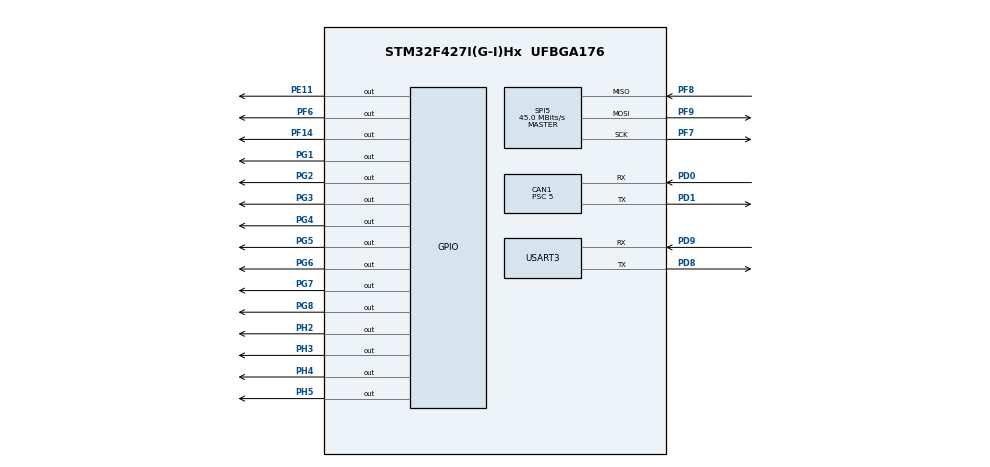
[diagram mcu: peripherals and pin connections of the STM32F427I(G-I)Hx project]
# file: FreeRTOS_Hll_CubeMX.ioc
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CAN1.ABOM=ENABLE
CAN1.BS1=CAN_BS1_3TQ
CAN1.BS2=CAN_BS2_5TQ
CAN1.CalculateBaudRate=1000000
CAN1.CalculateTimeBit=1000
CAN1.CalculateTimeQuantum=111.11111111111111
CAN1.Prescaler=5
Dma.Request0=SPI5_RX
Dma.Request1=SPI5_TX
Dma.SPI5_RX.0.Direction=DMA_PERIPH_TO_MEMORY
Dma.SPI5_RX.0.FIFOMode=DMA_FIFOMODE_DISABLE
Dma.SPI5_RX.0.Instance=DMA2_Stream5
Dma.SPI5_RX.0.MemDataAlignment=DMA_MDATAALIGN_BYTE
Dma.SPI5_RX.0.MemInc=DMA_MINC_ENABLE
Dma.SPI5_RX.0.Mode=DMA_NORMAL
Dma.SPI5_RX.0.PeriphDataAlignment=DMA_PDATAALIGN_BYTE
Dma.SPI5_RX.0.PeriphInc=DMA_PINC_DISABLE
Dma.SPI5_RX.0.Priority=DMA_PRIORITY_VERY_HIGH
Dma.SPI5_TX.1.Direction=DMA_MEMORY_TO_PERIPH
Dma.SPI5_TX.1.FIFOMode=DMA_FIFOMODE_DISABLE
Dma.SPI5_TX.1.Instance=DMA2_Stream4
Dma.SPI5_TX.1.MemDataAlignment=DMA_MDATAALIGN_BYTE
Dma.SPI5_TX.1.MemInc=DMA_MINC_ENABLE
Dma.SPI5_TX.1.Mode=DMA_NORMAL
Dma.SPI5_TX.1.PeriphDataAlignment=DMA_PDATAALIGN_BYTE
Dma.SPI5_TX.1.PeriphInc=DMA_PINC_DISABLE
Dma.SPI5_TX.1.Priority=DMA_PRIORITY_MEDIUM
FREERTOS.BinarySemaphores01=Remote_Sema,Dynamic,NULL
FREERTOS.Tasks01=defaultTask,24,128,StartDefaultTask,Default,NULL,Dynamic,NULL,NULL;REMOTE,24,256,Remote_Task,As weak,NULL,Dynamic,NULL,NULL;CHASSIS,24,256,Chassis_Take,As weak,NULL,Dynamic,NULL,NULL
Mcu.Family=STM32F4
Mcu.Name=STM32F427I(G-I)Hx
Mcu.Package=UFBGA176
NVIC.CAN1_RX0_IRQn=true\:5\:0\:false\:false\:true\:true\:true\:true\:true
NVIC.DMA2_Stream4_IRQn=true\:5\:0\:false\:false\:true\:true\:false\:true\:true
NVIC.DMA2_Stream5_IRQn=true\:5\:0\:false\:false\:true\:false\:false\:true\:true
NVIC.PriorityGroup=NVIC_PRIORITYGROUP_4
NVIC.SPI5_IRQn=true\:5\:0\:false\:false\:true\:true\:true\:true\:true
NVIC.TIM6_DAC_IRQn=true\:15\:0\:false\:false\:true\:false\:false\:true\:true
NVIC.TIM7_IRQn=true\:5\:0\:false\:false\:true\:true\:true\:true\:true
NVIC.TimeBase=TIM6_DAC_IRQn
NVIC.TimeBaseIP=TIM6
NVIC.USART3_IRQn=true\:5\:0\:false\:false\:true\:true\:true\:true\:true
PA13.Mode=Serial_Wire
PA13.Signal=SYS_JTMS-SWDIO
PA14.Mode=Serial_Wire
PA14.Signal=SYS_JTCK-SWCLK
PD0.Mode=CAN_Activate
PD0.Signal=CAN1_RX
PD1.Mode=CAN_Activate
PD1.Signal=CAN1_TX
PD8.Mode=Asynchronous
PD8.Signal=USART3_TX
PD9.Mode=Asynchronous
PD9.Signal=USART3_RX
PE11.GPIO_Speed=GPIO_SPEED_FREQ_VERY_HIGH
PE11.PinState=GPIO_PIN_SET
PE11.Signal=GPIO_Output
PF14.GPIO_Speed=GPIO_SPEED_FREQ_VERY_HIGH
PF14.PinState=GPIO_PIN_SET
PF14.Signal=GPIO_Output
PF6.GPIO_Speed=GPIO_SPEED_FREQ_VERY_HIGH
PF6.PinState=GPIO_PIN_RESET
PF6.Signal=GPIO_Output
PF7.Mode=Full_Duplex_Master
PF7.Signal=SPI5_SCK
PF8.Mode=Full_Duplex_Master
PF8.Signal=SPI5_MISO
PF9.Mode=Full_Duplex_Master
PF9.Signal=SPI5_MOSI
PG1.GPIO_ModeDefaultOutputPP=GPIO_MODE_OUTPUT_PP
PG1.GPIO_PuPd=GPIO_NOPULL
PG1.GPIO_Speed=GPIO_SPEED_FREQ_VERY_HIGH
PG1.PinState=GPIO_PIN_SET
PG1.Signal=GPIO_Output
PG2.GPIO_ModeDefaultOutputPP=GPIO_MODE_OUTPUT_PP
PG2.GPIO_PuPd=GPIO_NOPULL
PG2.GPIO_Speed=GPIO_SPEED_FREQ_VERY_HIGH
PG2.PinState=GPIO_PIN_SET
PG2.Signal=GPIO_Output
PG3.GPIO_ModeDefaultOutputPP=GPIO_MODE_OUTPUT_PP
PG3.GPIO_PuPd=GPIO_NOPULL
PG3.GPIO_Speed=GPIO_SPEED_FREQ_VERY_HIGH
PG3.PinState=GPIO_PIN_SET
PG3.Signal=GPIO_Output
PG4.GPIO_ModeDefaultOutputPP=GPIO_MODE_OUTPUT_PP
PG4.GPIO_PuPd=GPIO_NOPULL
PG4.GPIO_Speed=GPIO_SPEED_FREQ_VERY_HIGH
PG4.PinState=GPIO_PIN_SET
PG4.Signal=GPIO_Output
PG5.GPIO_ModeDefaultOutputPP=GPIO_MODE_OUTPUT_PP
PG5.GPIO_PuPd=GPIO_NOPULL
PG5.GPIO_Speed=GPIO_SPEED_FREQ_VERY_HIGH
PG5.PinState=GPIO_PIN_SET
PG5.Signal=GPIO_Output
PG6.GPIO_ModeDefaultOutputPP=GPIO_MODE_OUTPUT_PP
PG6.GPIO_PuPd=GPIO_NOPULL
PG6.GPIO_Speed=GPIO_SPEED_FREQ_VERY_HIGH
PG6.PinState=GPIO_PIN_SET
PG6.Signal=GPIO_Output
PG7.GPIO_ModeDefaultOutputPP=GPIO_MODE_OUTPUT_PP
PG7.GPIO_PuPd=GPIO_NOPULL
PG7.GPIO_Speed=GPIO_SPEED_FREQ_VERY_HIGH
PG7.PinState=GPIO_PIN_SET
PG7.Signal=GPIO_Output
PG8.GPIO_ModeDefaultOutputPP=GPIO_MODE_OUTPUT_PP
PG8.GPIO_PuPd=GPIO_NOPULL
PG8.GPIO_Speed=GPIO_SPEED_FREQ_VERY_HIGH
PG8.PinState=GPIO_PIN_SET
PG8.Signal=GPIO_Output
PH0/OSC_IN.Mode=HSE-External-Oscillator
PH0/OSC_IN.Signal=RCC_OSC_IN
PH1/OSC_OUT.Mode=HSE-External-Oscillator
PH1/OSC_OUT.Signal=RCC_OSC_OUT
PH2.GPIO_ModeDefaultOutputPP=GPIO_MODE_OUTPUT_PP
PH2.GPIO_PuPd=GPIO_NOPULL
PH2.GPIO_Speed=GPIO_SPEED_FREQ_VERY_HIGH
PH2.PinState=GPIO_PIN_RESET
PH2.Signal=GPIO_Output
PH3.GPIO_ModeDefaultOutputPP=GPIO_MODE_OUTPUT_PP
PH3.GPIO_PuPd=GPIO_NOPULL
PH3.GPIO_Speed=GPIO_SPEED_FREQ_VERY_HIGH
PH3.PinState=GPIO_PIN_RESET
PH3.Signal=GPIO_Output
PH4.GPIO_ModeDefaultOutputPP=GPIO_MODE_OUTPUT_PP
PH4.GPIO_PuPd=GPIO_NOPULL
PH4.GPIO_Speed=GPIO_SPEED_FREQ_VERY_HIGH
PH4.PinState=GPIO_PIN_RESET
PH4.Signal=GPIO_Output
PH5.GPIO_ModeDefaultOutputPP=GPIO_MODE_OUTPUT_PP
PH5.GPIO_PuPd=GPIO_NOPULL
PH5.GPIO_Speed=GPIO_SPEED_FREQ_VERY_HIGH
PH5.PinState=GPIO_PIN_RESET
PH5.Signal=GPIO_Output
ProjectManager.HeapSize=0x200
ProjectManager.StackSize=0x400
ProjectManager.TargetToolchain=MDK-ARM V5.32
RCC.48MHZClocksFreq_Value=90000000
RCC.AHBFreq_Value=180000000
RCC.APB1CLKDivider=RCC_HCLK_DIV4
RCC.APB1Freq_Value=45000000
RCC.APB1TimFreq_Value=90000000
RCC.APB2CLKDivider=RCC_HCLK_DIV2
RCC.APB2Freq_Value=90000000
RCC.APB2TimFreq_Value=180000000
RCC.CortexFreq_Value=180000000
RCC.HCLKFreq_Value=180000000
RCC.HSE_VALUE=12000000
RCC.HSI_VALUE=16000000
RCC.LSE_VALUE=32768
RCC.PLLM=6
RCC.PLLN=180
RCC.PLLSourceVirtual=RCC_PLLSOURCE_HSE
RCC.SYSCLKFreq_VALUE=180000000
RCC.SYSCLKSource=RCC_SYSCLKSOURCE_PLLCLK
RCC.VCOOutputFreq_Value=360000000
SPI5.CalculateBaudRate=45.0 MBits/s
SPI5.Direction=SPI_DIRECTION_2LINES
SPI5.Mode=SPI_MODE_MASTER
SPI5.VirtualType=VM_MASTER
TIM7.Period=9999
TIM7.Prescaler=89
USART3.VirtualMode=VM_ASYNC
VP_FREERTOS_VS_CMSIS_V2.Mode=CMSIS_V2
VP_SYS_VS_tim6.Mode=TIM6
VP_TIM7_VS_ClockSourceINT.Mode=Enable_Timer
board=custom

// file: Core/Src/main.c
/* USER CODE BEGIN Header */
/**
  ******************************************************************************
  * @file           : main.c
  * @brief          : Main program body
  ******************************************************************************
  * @attention
  *
  * Copyright (c) 2022 STMicroelectronics.
  * All rights reserved.
  *
  * This software is licensed under terms that can be found in the LICENSE file
  * in the root directory of this software component.
  * If no LICENSE file comes with this software, it is provided AS-IS.
  *
  ******************************************************************************
  */
/* USER CODE END Header */
#include "main.h"
#include "cmsis_os.h"
#include "can.h"
#include "dma.h"
#include "spi.h"
#include "tim.h"
#include "usart.h"
#include "gpio.h"

/* USER CODE BEGIN Includes */

#include "base_init.h"

/* USER CODE END Includes */

void SystemClock_Config(void);
void MX_FREERTOS_Init(void);

int main(void)
{

  /* MCU Configuration--------------------------------------------------------*/

  /* Reset of all peripherals, Initializes the Flash interface and the Systick. */
  HAL_Init();

  /* Configure the system clock */
  SystemClock_Config();

  /* Initialize all configured peripherals */
  MX_GPIO_Init();
  MX_DMA_Init();
  MX_CAN1_Init();
  MX_TIM7_Init();
  MX_USART3_UART_Init();
  MX_SPI5_Init();
  /* USER CODE BEGIN 2 */

  Init_Hardware();

  /* USER CODE END 2 */

  /* Init scheduler */
  osKernelInitialize();  /* Call init function for freertos objects (in freertos.c) */
  MX_FREERTOS_Init();

  /* Start scheduler */
  osKernelStart();

  /* We should never get here as control is now taken by the scheduler */
  /* Infinite loop */
  while (1)
  {

  }
}

void SystemClock_Config(void)
{
  LL_FLASH_SetLatency(LL_FLASH_LATENCY_5);
  while(LL_FLASH_GetLatency()!= LL_FLASH_LATENCY_5)
  {
  }
  LL_PWR_SetRegulVoltageScaling(LL_PWR_REGU_VOLTAGE_SCALE1);
  LL_PWR_EnableOverDriveMode();
  LL_RCC_HSE_Enable();

   /* Wait till HSE is ready */
  while(LL_RCC_HSE_IsReady() != 1)
  {

  }
  LL_RCC_PLL_ConfigDomain_SYS(LL_RCC_PLLSOURCE_HSE, LL_RCC_PLLM_DIV_6, 180, LL_RCC_PLLP_DIV_2);
  LL_RCC_PLL_Enable();

   /* Wait till PLL is ready */
  while(LL_RCC_PLL_IsReady() != 1)
  {

  }
  LL_RCC_SetAHBPrescaler(LL_RCC_SYSCLK_DIV_1);
  LL_RCC_SetAPB1Prescaler(LL_RCC_APB1_DIV_4);
  LL_RCC_SetAPB2Prescaler(LL_RCC_APB2_DIV_2);
  LL_RCC_SetSysClkSource(LL_RCC_SYS_CLKSOURCE_PLL);

   /* Wait till System clock is ready */
  while(LL_RCC_GetSysClkSource() != LL_RCC_SYS_CLKSOURCE_STATUS_PLL)
  {

  }
  LL_SetSystemCoreClock(180000000);

   /* Update the time base */
  if (HAL_InitTick (TICK_INT_PRIORITY) != HAL_OK)
  {
    Error_Handler();
  }
  LL_RCC_SetTIMPrescaler(LL_RCC_TIM_PRESCALER_TWICE);
}

void HAL_TIM_PeriodElapsedCallback(TIM_HandleTypeDef *htim)
{
  if (htim->Instance == TIM6) {
    HAL_IncTick();
  }
}

void Error_Handler(void)
{
  __disable_irq();
  while (1)
  {
  }
}

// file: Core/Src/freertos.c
/* USER CODE BEGIN Header */
/**
  ******************************************************************************
  * File Name          : freertos.c
  * Description        : Code for freertos applications
  ******************************************************************************
  * @attention
  *
  * Copyright (c) 2022 STMicroelectronics.
  * All rights reserved.
  *
  * This software is licensed under terms that can be found in the LICENSE file
  * in the root directory of this software component.
  * If no LICENSE file comes with this software, it is provided AS-IS.
  *
  ******************************************************************************
  */
/* USER CODE END Header */

#include "FreeRTOS.h"
#include "task.h"
#include "main.h"
#include "cmsis_os.h"

/* Definitions for defaultTask */
osThreadId_t defaultTaskHandle;
const osThreadAttr_t defaultTask_attributes = {
  .name = "defaultTask",
  .stack_size = 128 * 4,
  .priority = (osPriority_t) osPriorityNormal,
};
/* Definitions for REMOTE */
osThreadId_t REMOTEHandle;
const osThreadAttr_t REMOTE_attributes = {
  .name = "REMOTE",
  .stack_size = 256 * 4,
  .priority = (osPriority_t) osPriorityNormal,
};
/* Definitions for CHASSIS */
osThreadId_t CHASSISHandle;
const osThreadAttr_t CHASSIS_attributes = {
  .name = "CHASSIS",
  .stack_size = 256 * 4,
  .priority = (osPriority_t) osPriorityNormal,
};
/* Definitions for Remote_Sema */
osSemaphoreId_t Remote_SemaHandle;
const osSemaphoreAttr_t Remote_Sema_attributes = {
  .name = "Remote_Sema"
};

void StartDefaultTask(void *argument);
void Remote_Task(void *argument);
void Chassis_Take(void *argument);

void MX_FREERTOS_Init(void); /* (MISRA C 2004 rule 8.1) */

void MX_FREERTOS_Init(void) {

  /* Create the semaphores(s) */
  /* creation of Remote_Sema */
  Remote_SemaHandle = osSemaphoreNew(1, 1, &Remote_Sema_attributes);

  /* Create the thread(s) */
  /* creation of defaultTask */
  defaultTaskHandle = osThreadNew(StartDefaultTask, NULL, &defaultTask_attributes);

  /* creation of REMOTE */
  REMOTEHandle = osThreadNew(Remote_Task, NULL, &REMOTE_attributes);

  /* creation of CHASSIS */
  CHASSISHandle = osThreadNew(Chassis_Take, NULL, &CHASSIS_attributes);

}

void StartDefaultTask(void *argument)
{
  for(;;)
  {
    osDelay(1);
  }
}

__weak void Remote_Task(void *argument)
{
  for(;;)
  {
    osDelay(1);
  }
}

__weak void Chassis_Take(void *argument)
{
  for(;;)
  {
    osDelay(1);
  }
}
